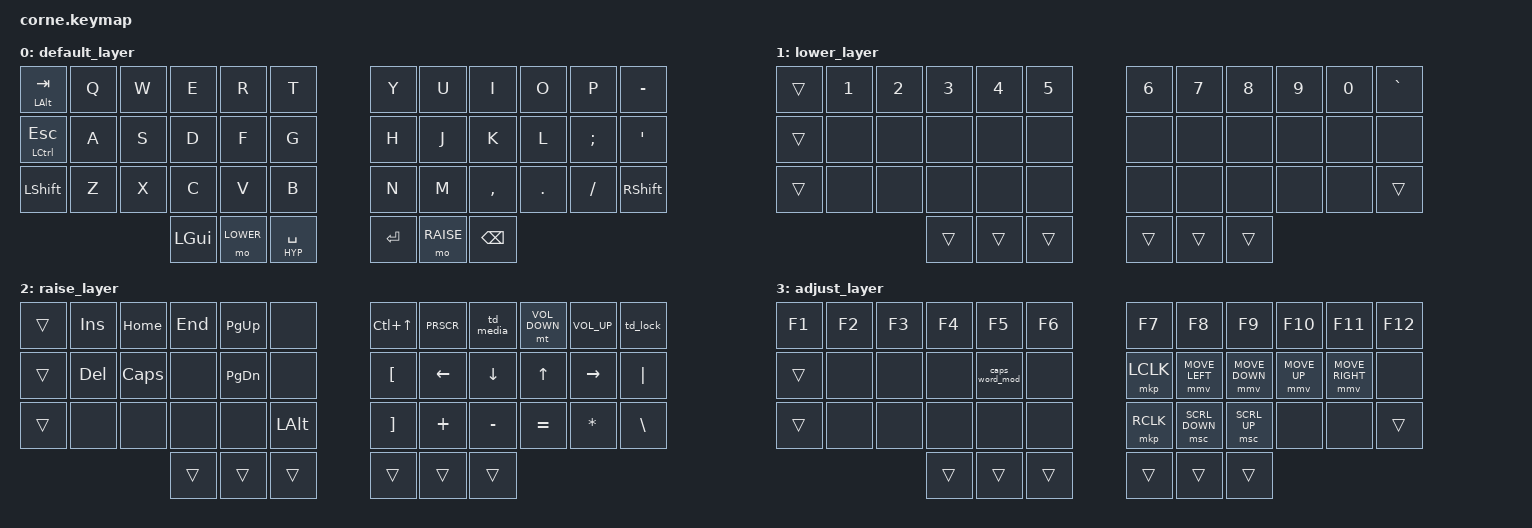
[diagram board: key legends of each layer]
/*
 * Copyright (c) 2022 Aleksandar Diklic
 *
  * SPDX-License-Identifier: MIT
 */

#include <behaviors.dtsi>
#include <dt-bindings/zmk/keys.h>
#include <dt-bindings/zmk/bt.h>
#include <dt-bindings/zmk/mouse.h>

#define TAPPING_TERM 200
#define COMBO_TIMEOUT 40

#define DEFAULT 0
#define LOWER 1
#define RAISE 2
#define ADJUST 3

#define HYP LS(LC(LA(LGUI)))
#define PRSCR LS(LC(LG(N4)))

// Friendlier volume definitions, tap volume down, hold mute
#define VOLUME_DOWN K_MUTE C_VOLUME_DOWN
#define VOLUME_UP C_VOLUME_UP

&kscan0 {
    debounce-press-ms = <10>;
    debounce-release-ms = <10>;
};

&mt {
    tapping-term-ms = <TAPPING_TERM>;
    flavor = "tap-preferred";
};

/ {
  behaviors {
    /*
    * td_media mimics the behavior of AirPods controls:
    *  - tap once for play / pause
    *  - tap twice for next track
    *  - tap three times for previous track
    */
    td_media: tap_dance_media {
      compatible = "zmk,behavior-tap-dance";
      label = "TAP_DANCE_MEDIA";
      #binding-cells = <0>;
      tapping-term-ms = <TAPPING_TERM>;
      bindings = <&kp C_PLAY_PAUSE>, <&kp C_NEXT>, <&kp C_PREVIOUS>;
    };

    /*
    * td_lock groups locking functions into one key:
    *  - tap once to lock the host
    *  - tap twice to put the host to sleep
    */
    td_lock: tap_dance_lock {
      compatible = "zmk,behavior-tap-dance";
      label = "TAP_DANCE_LOCK";
      #binding-cells = <0>;
      tapping-term-ms = <TAPPING_TERM>;
      bindings = <&kp LG(LC(Q))>, <&kp LG(LA(C_EJECT))>;
    };

    /*
    * Caps Word allows typing in UPPERCASE without holding shift.
    * It deactivates when a non-alphabetic key is pressed.
    */
    caps_word_mod: capsword_behavior {
      compatible = "zmk,behavior-caps-word";
      label = "CAPS_WORD";
      #binding-cells = <0>;
      continue-list = <UNDERSCORE MINUS>;
    };
  };

  conditional_layers {
    compatible = "zmk,conditional-layers";
    tri_layer {
      if-layers = <LOWER RAISE>;
      then-layer = <ADJUST>;
    };
  };

  keymap {
    compatible = "zmk,keymap";

    // key positions
    /* --------------------------------------------------------------------------------
    *  |  0  |  1  |  2  |  3  |  4  |  5  |     |  6  |  7  |  8  |  9  |  10 |  11 |
    *  |  12 |  13 |  14 |  15 |  16 |  17 |     |  18 |  19 |  20 |  21 |  22 |  23 |
    *  |  24 |  25 |  26 |  27 |  28 |  29 |     |  30 |  31 |  32 |  33 |  34 |  35 |
    *                    |  36 |  37 |  38 |     |  39 |  40 |  41 |
    */

    default_layer {
     bindings = <
        /*
         * |  TAB/ALT |  Q  |  W  |  E  |  R  |  T  |   |  Y  |  U   |  I  |  O  |  P  |  -   |
         * | ESC/CTRL |  A  |  S  |  D  |  F  |  G  |   |  H  |  J   |  K  |  L  |  ;  |  '   |
         * |  SHIFT   |  Z  |  X  |  C  |  V  |  B  |   |  N  |  M   |  ,  |  .  |  /  | SHIFT|
         *                        | GUI | LWR | SPC |   | ENT | RSE  | BKSP|
         */
        &mt LALT TAB &kp Q &kp W &kp E    &kp R     &kp T             &kp Y   &kp U     &kp I     &kp O   &kp P    &kp MINUS
        &mt LCTL ESC &kp A &kp S &kp D    &kp F     &kp G             &kp H   &kp J     &kp K     &kp L   &kp SEMI &kp SQT
        &kp LSHFT    &kp Z &kp X &kp C    &kp V     &kp B             &kp N   &kp M     &kp COMMA &kp DOT &kp FSLH &kp RSHFT
                                 &kp LGUI &mo LOWER &mt HYP SPACE     &kp RET &mo RAISE &kp BSPC
      >;
    };

    lower_layer {
     bindings = <
        /*
         * |  TAB  |  1  |  2  |  3  |  4  |  5  |   |  6  |  7  |  8  |  9  |  0  |  `   |
         * | CTRL  |     |     |     |     |     |   |     |     |     |     |     |      |
         * | SHIFT |     |     |     |     |     |   |     |     |     |     |     | SHIFT|
         *                     | GUI |     | SPC |   | ENT |     | BKSP|
         */
        &trans &kp N1       &kp N2       &kp N3       &kp N4       &kp N5         &kp N6 &kp N7 &kp N8 &kp N9 &kp N0 &kp GRAVE
        &trans &none        &none        &none        &none        &none          &none  &none  &none  &none  &none  &none
        &trans &none        &none        &none        &none        &none          &none  &none  &none  &none  &none  &trans
                                        &trans       &trans       &trans         &trans &trans &trans
      >;
    };

    raise_layer {
     bindings = <
        /*
         * | TAB  | INS | HOME| END | PGUP|     |   |C+UP |PRTSC|MEDIA|VOL- |VOL+ | LOCK |
         * | CTRL | DEL | CAPS|     | PGDN|     |   |  [  | LFT | DWN | UP  | RGT |  |   |
         * | SHFT |     |     |     |     | ALT |   |  ]  |  +  |  -  |  =  |  *  |  \   |
         *                    | GUI |     | SPC |   | ENT |     | BKSP|
         */
        &trans &kp INS  &kp HOME &kp END  &kp PG_UP &none      &kp LC(UP) &kp PRSCR &td_media &mt VOLUME_DOWN &kp VOLUME_UP  &td_lock
        &trans &kp DEL  &kp CAPS &none    &kp PG_DN &none      &kp LBKT   &kp LEFT  &kp DOWN  &kp UP          &kp RIGHT      &kp PIPE
        &trans &none    &none    &none    &none &kp LALT       &kp RBKT   &kp PLUS  &kp MINUS &kp EQUAL       &kp STAR       &kp BSLH      
                                 &trans   &trans    &trans     &trans     &trans    &trans
      >;
    };

    adjust_layer {
     bindings = <
        /*
         * | F1  | F2  | F3  | F4  | F5  | F6  |   | F7  | F8  | F9  | F10 | F11 | F12 |
         * |     |     |     |     |CWORD|     |   |LCLK |M-LFT|M-DN |M-UP |M-RGT|     |
         * |     |     |     |     |     |     |   |RCLK |SCDN |SCUP |     |     |     |
         *                   |     |     |     |   |     |     |     |
         */
        &kp F1 &kp F2 &kp F3 &kp F4  &kp F5       &kp F6      &kp F7    &kp F8         &kp F9         &kp F10      &kp F11         &kp F12
        &trans &none  &none  &none   &caps_word_mod &none     &mkp LCLK &mmv MOVE_LEFT &mmv MOVE_DOWN &mmv MOVE_UP &mmv MOVE_RIGHT &none
        &trans &none  &none  &none   &none         &none      &mkp RCLK &msc SCRL_DOWN &msc SCRL_UP   &none        &none           &trans
                             &trans  &trans        &trans     &trans    &trans      &trans
      >;
    };
  };
};
